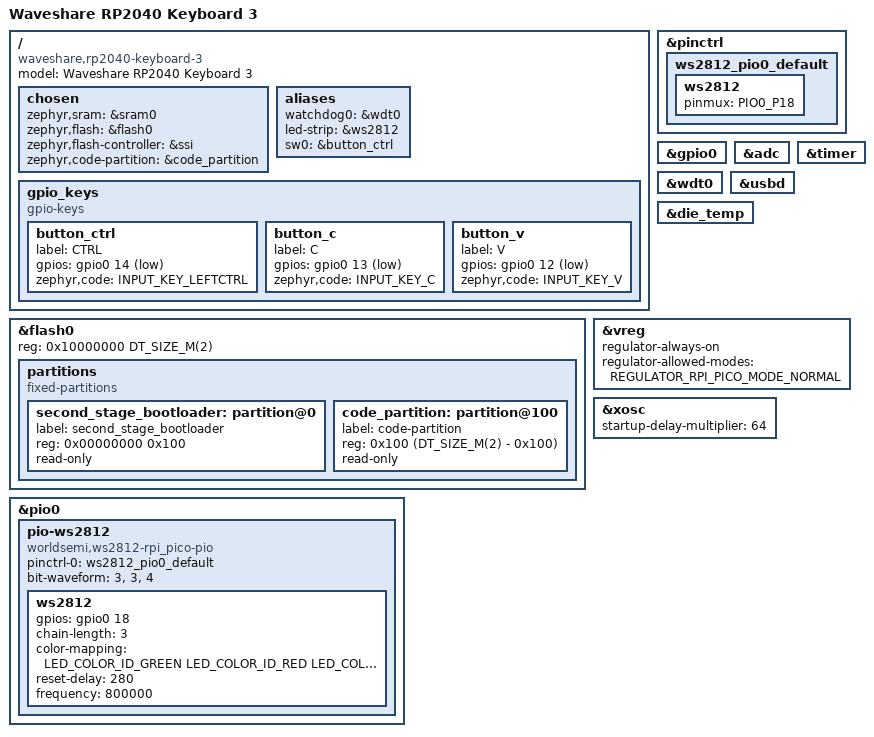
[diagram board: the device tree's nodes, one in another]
/*
 * Copyright (c) 2021 Yonatan Schachter
 * Copyright (c) 2022 Peter Johanson
 * Copyright (c) 2025 Jonas Berg
 *
 * SPDX-License-Identifier: Apache-2.0
 */

/dts-v1/;

#include <raspberrypi/rpi_pico/rp2040.dtsi>
#include <dt-bindings/pinctrl/rpi-pico-rp2040-pinctrl.h>
#include <zephyr/dt-bindings/input/input-event-codes.h>
#include <zephyr/dt-bindings/led/led.h>

/ {
	model = "Waveshare RP2040 Keyboard 3";
	compatible = "waveshare,rp2040-keyboard-3";

	chosen {
		zephyr,sram = &sram0;
		zephyr,flash = &flash0;
		zephyr,flash-controller = &ssi;
		zephyr,code-partition = &code_partition;
	};

	aliases {
		watchdog0 = &wdt0;
		led-strip = &ws2812;
		sw0 = &button_ctrl;
	};

	gpio_keys {
		compatible = "gpio-keys";

		button_ctrl: button_ctrl {
			label = "CTRL";
			gpios = <&gpio0 14 (GPIO_ACTIVE_LOW | GPIO_PULL_UP)>;
			zephyr,code = <INPUT_KEY_LEFTCTRL>;
		};

		button_c: button_c {
			label = "C";
			gpios = <&gpio0 13 (GPIO_ACTIVE_LOW | GPIO_PULL_UP)>;
			zephyr,code = <INPUT_KEY_C>;
		};

		button_v: button_v {
			label = "V";
			gpios = <&gpio0 12 (GPIO_ACTIVE_LOW | GPIO_PULL_UP)>;
			zephyr,code = <INPUT_KEY_V>;
		};
	};
};

&pinctrl {
	ws2812_pio0_default: ws2812_pio0_default {
		ws2812 {
			pinmux = <PIO0_P18>;
		};
	};
};

&flash0 {
	reg = <0x10000000 DT_SIZE_M(2)>;

	partitions {
		compatible = "fixed-partitions";
		#address-cells = <1>;
		#size-cells = <1>;

		/* Reserved memory for the second stage bootloader */
		second_stage_bootloader: partition@0 {
			label = "second_stage_bootloader";
			reg = <0x00000000 0x100>;
			read-only;
		};

		/*
		 * Usable flash. Starts at 0x100, after the bootloader. The partition
		 * size is 2 MB minus the 0x100 bytes taken by the bootloader.
		 */
		code_partition: partition@100 {
			label = "code-partition";
			reg = <0x100 (DT_SIZE_M(2) - 0x100)>;
			read-only;
		};
	};
};

&gpio0 {
	status = "okay";
};

&adc {
	status = "okay";
	#address-cells = <1>;
	#size-cells = <0>;
};

&timer {
	status = "okay";
};

&wdt0 {
	status = "okay";
};

&pio0 {
	status = "okay";

	pio-ws2812 {
		compatible = "worldsemi,ws2812-rpi_pico-pio";
		status = "okay";
		pinctrl-0 = <&ws2812_pio0_default>;
		pinctrl-names = "default";
		bit-waveform = <3>, <3>, <4>;

		ws2812: ws2812 {
			status = "okay";
			gpios = <&gpio0 18 GPIO_ACTIVE_HIGH>;
			chain-length = <3>;
			color-mapping = <LED_COLOR_ID_GREEN
				LED_COLOR_ID_RED
				LED_COLOR_ID_BLUE>;
			reset-delay = <280>;
			frequency = <800000>;
		};
	};
};

zephyr_udc0: &usbd {
	status = "okay";
};

&die_temp {
	status = "okay";
};

&vreg {
	regulator-always-on;
	regulator-allowed-modes = <REGULATOR_RPI_PICO_MODE_NORMAL>;
};

&xosc {
	startup-delay-multiplier = <64>;
};

#include <../boards/common/usb/cdc_acm_serial.dtsi>
